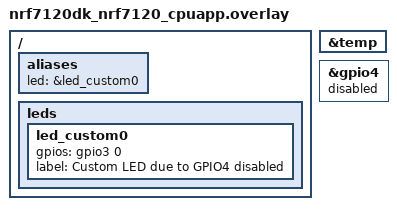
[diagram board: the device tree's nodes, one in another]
/ {
	aliases {
		led = &led_custom0;
	};

	leds {
		led_custom0: led_custom0 {
			gpios = <&gpio3 0 GPIO_ACTIVE_HIGH>;
			label = "Custom LED due to GPIO4 disabled";
		};
	};
};

temp_sensor: &temp {
	status = "okay";
};

&gpio4 {
	status = "disabled";
};
